AUTOSAR XML (schema 4-3-0)
package /PEPS/ComponentTypes_PEPS
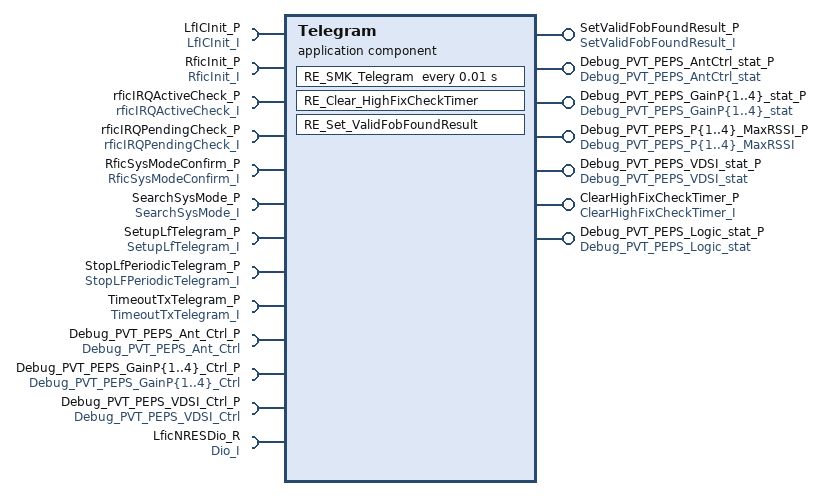
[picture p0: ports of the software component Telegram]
  application sw component type Telegram  # This Application SWC is for Telegram function.
    provide port SetValidFobFoundResult_P: server-com-spec{operation=CS, queue-length=1}, provided-interface=SetValidFobFoundResult_I
    9 x require port:
      LfICInit_P: client-com-spec=CS, required-interface=LfICInit_I
      RficInit_P: client-com-spec=CS, required-interface=RficInit_I
      rficIRQActiveCheck_P: client-com-spec=CS, required-interface=rficIRQActiveCheck_I
      rficIRQPendingCheck_P: client-com-spec=CS, required-interface=rficIRQPendingCheck_I
      RficSysModeConfirm_P: nonqueued-receiver-com-spec{data-element=SR_RficSysModeConfirm, filter=data-filter-type=ALWAYS, init-value=0}, required-interface=RficSysModeConfirm_I
      SearchSysMode_P: client-com-spec=CS, required-interface=SearchSysMode_I
      SetupLfTelegram_P: client-com-spec=CS, required-interface=SetupLfTelegram_I
      StopLfPeriodicTelegram_P: client-com-spec=CS, required-interface=StopLFPeriodicTelegram_I
      TimeoutTxTelegram_P: client-com-spec=CS, required-interface=TimeoutTxTelegram_I
    10 x provide port:
      Debug_PVT_PEPS_AntCtrl_stat_P: nonqueued-sender-com-spec{data-element=Debug_PVT_PEPS_AntCtrl_stat, init-value=0}, provided-interface=Debug_PVT_PEPS_AntCtrl_stat
      Debug_PVT_PEPS_GainP{1..4}_stat_P: nonqueued-sender-com-spec{data-element=Debug_PVT_PEPS_GainP{1..4}_stat, init-value=0}, provided-interface=Debug_PVT_PEPS_GainP{1..4}_stat
      Debug_PVT_PEPS_P{1..4}_MaxRSSI_P: nonqueued-sender-com-spec{data-element=Debug_PVT_PEPS_P{1..4}_MaxRSSI, init-value=0}, provided-interface=Debug_PVT_PEPS_P{1..4}_MaxRSSI
      Debug_PVT_PEPS_VDSI_stat_P: nonqueued-sender-com-spec{data-element=Debug_PVT_PEPS_VDSI_stat, init-value=0}, provided-interface=Debug_PVT_PEPS_VDSI_stat
    7 x require port:
      Debug_PVT_PEPS_Ant_Ctrl_P: nonqueued-receiver-com-spec{data-element=Debug_PVT_PEPS_Ant_Ctrl, filter=data-filter-type=ALWAYS, init-value=0}, required-interface=Debug_PVT_PEPS_Ant_Ctrl
      Debug_PVT_PEPS_GainP{1..4}_Ctrl_P: nonqueued-receiver-com-spec{data-element=Debug_PVT_PEPS_GainP{1..4}_Ctrl, filter=data-filter-type=ALWAYS, init-value=0}, required-interface=Debug_PVT_PEPS_GainP{1..4}_Ctrl
      Debug_PVT_PEPS_VDSI_Ctrl_P: nonqueued-receiver-com-spec{data-element=Debug_PVT_PEPS_VDSI_Ctrl, filter=data-filter-type=ALWAYS, init-value=0}, required-interface=Debug_PVT_PEPS_VDSI_Ctrl
      LficNRESDio_R: required-com-specs=[Read, Write], required-interface=Dio_I
    provide port ClearHighFixCheckTimer_P: server-com-spec{operation=CS, queue-length=1}, provided-interface=ClearHighFixCheckTimer_I
    provide port Debug_PVT_PEPS_Logic_stat_P: nonqueued-sender-com-spec{data-element=Debug_PVT_PEPS_Logic_stat, init-value=0}, provided-interface=Debug_PVT_PEPS_Logic_stat
    behavior Telegram_InternalBehavior
      operation invoked event OIE_RE_Set_ValidFobFoundResult_SetValidFobFoundResult_P_CS: start-on-event=RE_Set_ValidFobFoundResult, operation=SetValidFobFoundResult_P.CS
      timing event TMT_RE_SMK_Telegram: start-on-event=RE_SMK_Telegram, period=0.01
      operation invoked event OIT_RE_Clear_HighFixCheckTimer_ClearHighFixCheckTimer_P_CS: start-on-event=RE_Clear_HighFixCheckTimer, operation=ClearHighFixCheckTimer_P.CS
      runnable RE_Clear_HighFixCheckTimer  # This runnable is to cancel and start timer_rficIRQHighTimeout.
      runnable RE_Set_ValidFobFoundResult  # This runnable is to set valid fob found result.
      runnable RE_SMK_Telegram
        data-receive-point-by-arguments:
          7 x access:
            DRPBA_RE_SMK_Telegram_RficSysModeConfirm_P_SR: accessed-variable=RficSysModeConfirm_P.SR_RficSysModeConfirm
            REC_Debug_PVT_PEPS_Ant_Ctrl_P_Debug_PVT_PEPS_Ant_Ctrl: accessed-variable=Debug_PVT_PEPS_Ant_Ctrl_P.Debug_PVT_PEPS_Ant_Ctrl
            REC_Debug_PVT_PEPS_GainP{1..4}_Ctrl_P_Debug_PVT_PEPS_GainP{1..4}_Ctrl: accessed-variable=Debug_PVT_PEPS_GainP{1..4}_Ctrl_P.Debug_PVT_PEPS_GainP{1..4}_Ctrl
            REC_Debug_PVT_PEPS_VDSI_Ctrl_P_Debug_PVT_PEPS_VDSI_Ctrl: accessed-variable=Debug_PVT_PEPS_VDSI_Ctrl_P.Debug_PVT_PEPS_VDSI_Ctrl
        data-send-points:
          11 x access:
            SEND_Debug_PVT_PEPS_AntCtrl_stat_P_Debug_PVT_PEPS_AntCtrl_stat: accessed-variable=Debug_PVT_PEPS_AntCtrl_stat_P.Debug_PVT_PEPS_AntCtrl_stat
            SEND_Debug_PVT_PEPS_GainP{1..4}_stat_P_Debug_PVT_PEPS_GainP{1..4}_stat: accessed-variable=Debug_PVT_PEPS_GainP{1..4}_stat_P.Debug_PVT_PEPS_GainP{1..4}_stat
            SEND_Debug_PVT_PEPS_P{1..4}_MaxRSSI_P_Debug_PVT_PEPS_P{1..4}_MaxRSSI: accessed-variable=Debug_PVT_PEPS_P{1..4}_MaxRSSI_P.Debug_PVT_PEPS_P{1..4}_MaxRSSI
            SEND_Debug_PVT_PEPS_VDSI_stat_P_Debug_PVT_PEPS_VDSI_stat: accessed-variable=Debug_PVT_PEPS_VDSI_stat_P.Debug_PVT_PEPS_VDSI_stat
            SEND_Debug_PVT_PEPS_Logic_stat_P_Debug_PVT_PEPS_Logic_stat: accessed-variable=Debug_PVT_PEPS_Logic_stat_P.Debug_PVT_PEPS_Logic_stat
        9 x sync call:
          SSCP_RE_SMK_Telegram_LfICInit_P_CS: operation=LfICInit_P.CS
          SSCP_RE_SMK_Telegram_RficInit_P_CS: operation=RficInit_P.CS
          SSCP_RE_SMK_Telegram_rficIRQActiveCheck_P_CS: operation=rficIRQActiveCheck_P.CS
          SSCP_RE_SMK_Telegram_rficIRQPendingCheck_P_CS: operation=rficIRQPendingCheck_P.CS
          SSCP_RE_SMK_Telegram_SearchSysMode_P_CS: operation=SearchSysMode_P.CS
          SSCP_RE_SMK_Telegram_SetupLfTelegram_P_CS: operation=SetupLfTelegram_P.CS
          SSCP_RE_SMK_Telegram_StopLfPeriodicTelegram_P_CS: operation=StopLfPeriodicTelegram_P.CS
          SSCP_RE_SMK_Telegram_TimeoutTxTelegram_P_CS: operation=TimeoutTxTelegram_P.CS
          SC_LficNRESDio_R_Write: operation=LficNRESDio_R.Write
  swc implementation Telegram_Implementation: behavior=Telegram_InternalBehavior
    code-descriptors:
      code Default: artifact-descriptors=autosar-engineering-object=category=SWSRC
